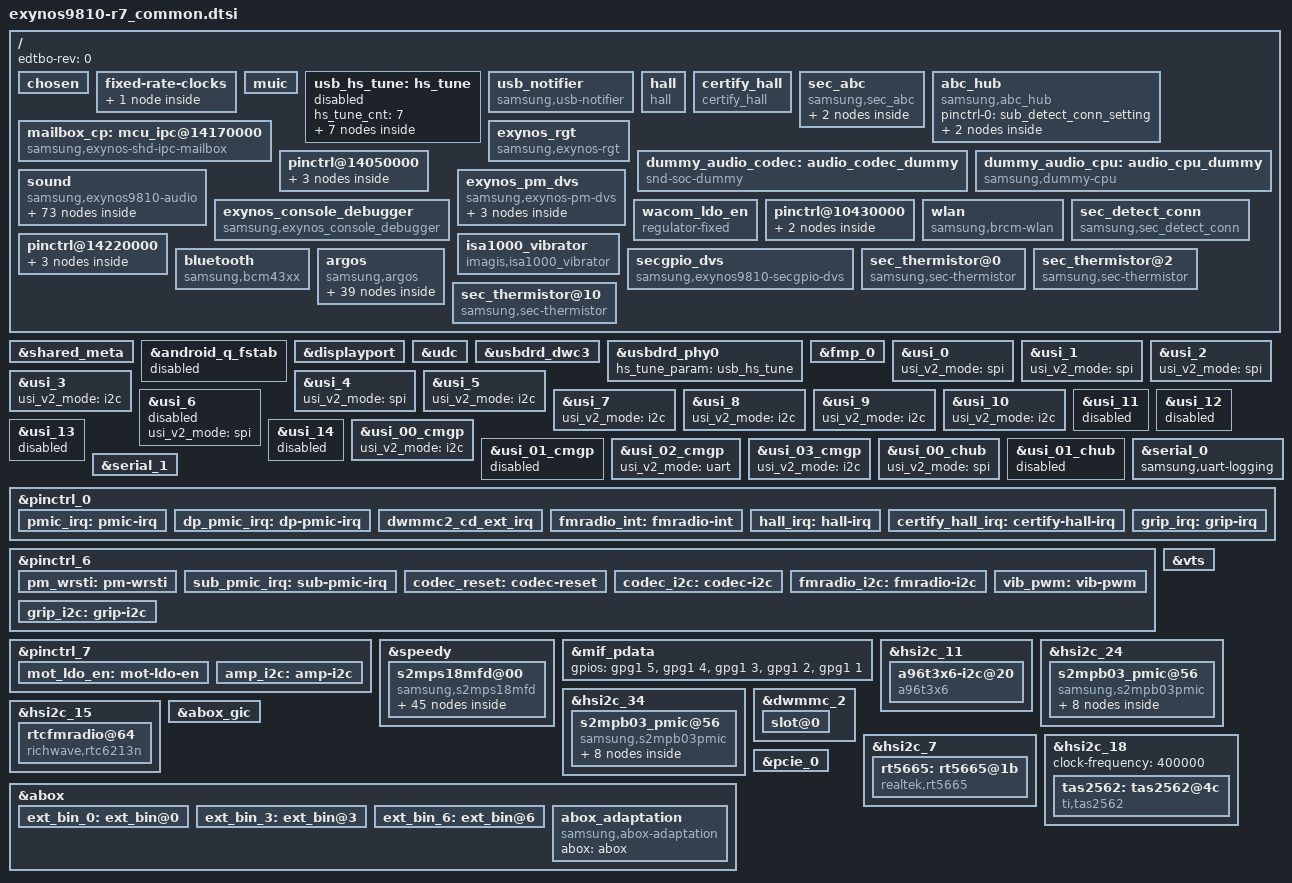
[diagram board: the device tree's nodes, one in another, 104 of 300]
/*
 * SAMSUNG EXYNOS9810 board device tree source
 *
 * Copyright (c) 2017 Samsung Electronics Co., Ltd.
 *		http://www.samsung.com
 *
 * This program is free software; you can redistribute it and/or modify
 * it under the terms of the GNU General Public License version 2 as
 * published by the Free Software Foundation.
*/

#include <dt-bindings/clock/exynos9810.h>
#include <dt-bindings/interrupt-controller/exynos9810.h>
#include <dt-bindings/camera/fimc_is.h>
#include <dt-bindings/pci/pci.h>
#include "display-lcd_anote_common.dtsi"
#include "modem-ss360ap-sipc-pdata.dtsi"
#include "exynos9810-r7_camera.dtsi"
#include "exynos9810-r7_mst.dtsi"
#include <dt-bindings/gpio/gpio.h>
#include "exynos9810-r7_input_common.dtsi"
#include "exynos9810-rmem_r7.dtsi"

/ {
	edtbo-rev = <0>;

	chosen: chosen {
		bootargs = "console=ram skip_initramfs rootwait ro root=/dev/ram0 init=/init clk_ignore_unused bcm_setup=0xffffff80f8e00000 androidboot.hardware=samsungexynos9810 androidboot.selinux=permissive androidboot.debug_level=0x4948 firmware_class.path=/vendor/firmware ecd_setup=disable reserve-fimc=0xffffff80f9fe0000 pmic_info=0x3 epx_activate=true";
	};

	fragment@model {
		target-path = "/";
		__overlay__ {
			#address-cells = <2>;
			#size-cells = <1>;

			fixed-rate-clocks {
				oscclk {
					compatible = "samsung,exynos9810-oscclk";
					clock-frequency = <26000000>;
				};
			};

			muic {
				new_factory;
				dcd_timeout;
			};

			usb_hs_tune:hs_tune {
				status = "disabled";
				hs_tune_cnt = <7>;
				/* value = <device host> */
				hs_tune1 {
					tune_name = "tx_pre_emp";
					tune_value = <0x3 0x3>;
				};

				hs_tune2 {
					tune_name = "tx_vref";
					tune_value = <0xf 0xd>;
				};

				hs_tune3 {
					tune_name = "rx_sqrx";
					tune_value = <0x7 0x7>;
				};

				hs_tune4 {
					tune_name = "compdis";
					tune_value = <0x7 0x7>;
				};

				hs_tune5 {
					tune_name = "tx_res";
					tune_value = <0x3 0x3>;
				};

				hs_tune6 {
					tune_name = "tx_rise";
					tune_value = <0x1 0x1>;
				};

				hs_tune7 {
					tune_name = "utmi_clk";
					tune_value = <0x1 0x1>;
				};
			};

			usb_notifier {
				compatible = "samsung,usb-notifier";
				udc = <&udc>;
				/*
				 * USB_LDOCONTROL_EXYNOS8895	1
				 * USB_LDOCONTROL_EXYNOS9810	2
				*/
				usb-ldocontrol = <2>;
			};

			hall {
				status = "okay";
				compatible = "hall";
				pinctrl-names = "default";
				pinctrl-0 = <&hall_irq>;
				hall,gpio_flip_cover = <&gpa0 2 0>;
			};

			certify_hall {
				status = "okay";
				compatible = "certify_hall";
				pinctrl-names = "default";
				pinctrl-0 = <&certify_hall_irq>;
				certify_hall,gpio_certify_cover = <&gpa3 6 0>;
			};

			sec_abc {
				compatible = "samsung,sec_abc";
				status = "okay";

				gpu {
					gpu,label="GPU fault";
					gpu,threshold_count=<20>;
					gpu,threshold_time=<1200>;
				};
				aicl {
					aicl,label="battery aicl";
					aicl,threshold_count=<5>;
					aicl,threshold_time=<300>;
				};
			};

			abc_hub {
				compatible = "samsung,abc_hub";
				status = "okay";

				pinctrl-names = "default";
				pinctrl-0 = <&sub_detect_conn_setting>;
				
				cond {
					cond,det_conn_gpios = <&gpm6 0 0>;             /* SUB_DET */

					cond,name="sub_cond";
					cond,det_conn_irq_type =<3>; /* SUB_DET BOTH EDGE*/
				};

				bootc {
					bootc,time_spec_user = <100000>; /* user binary user build */
					bootc,time_spec_eng = <100000>; /* user binary eng build */
					bootc,time_spec_fac = <100000>; /* factory binary */
				};
			};

			mailbox_cp: mcu_ipc@14170000 {
				compatible = "samsung,exynos-shd-ipc-mailbox";
				reg = <0x0 0x14170000 0x180>;
				mcu,name = "mcu_ipc_cp";
				mcu,id = <0>;
				interrupts = <0 INTREQ__MAILBOX_CP2AP 0 >;
			};

			exynos_rgt {
			        compatible = "samsung,exynos-rgt";
			};

			dummy_audio_codec: audio_codec_dummy {
				status = "okay";
				compatible = "snd-soc-dummy";
			};

			dummy_audio_cpu: audio_cpu_dummy {
				compatible = "samsung,dummy-cpu";
				status = "okay";
			};

			pinctrl@14050000 {
				codec_irq: codec-irq {
					samsung,pins = "gpa2-2";
					samsung,pin-function = <0xf>;
					samsung,pin-pud = <0>;
				};
			};
			sound {
				status = "okay";
				compatible = "samsung,exynos9810-audio";

				clock-names = "xclkout";
				clocks = <&clock OSC_AUD>;

				samsung,routing =
					"HEADSETMIC", "MICBIAS1",
					"MAINMIC", "MICBIAS2",
					"SUBMIC", "MICBIAS3",
					"IN1P", "HEADSETMIC",
					"IN1N", "HEADSETMIC",
					"IN2P", "MAINMIC",
					"IN2N", "MAINMIC",
					"IN3P", "FM",
					"IN3N", "FM",
					"IN4P", "SUBMIC",
					"IN4N", "SUBMIC",
					"RECEIVER", "MONOOUT",
					"RECEIVER", "MONOOUT",
					"HEADPHONE", "HPOL",
					"HEADPHONE", "HPOR",
					"BLUETOOTH SPK", "ABOX UAIF3 Playback",
					"ABOX UAIF3 Capture", "BLUETOOTH MIC",
					"VOUTPUT", "ABOX UAIF0 Playback",
					"ABOX UAIF1 Capture", "VINPUT1",
					"SPEAKER", "OUT",
					"VOUTPUTCALL", "ABOX UAIF2 Playback",
					"ABOX UAIF2 Capture", "VINPUTCALL";

				samsung,codec = <&abox &abox_uaif_0 &abox_uaif_1 &abox_uaif_2
					&abox_uaif_3 &abox_dsif &vts>;
				samsung,aux = <&abox_effect>;

				rdma@0 {
					cpu {
						sound-dai = <&abox 0>;
					};
					codec {
						sound-dai = <&dummy_audio_codec>;
					};
				};
				rdma@1 {
					cpu {
						sound-dai = <&abox 1>;
					};
					codec {
						sound-dai = <&dummy_audio_codec>;
					};
				};
				rdma@2 {
					cpu {
						sound-dai = <&abox 2>;
					};
					codec {
						sound-dai = <&dummy_audio_codec>;
					};
				};
				rdma@3 {
					cpu {
						sound-dai = <&abox 3>;
					};
					codec {
						sound-dai = <&dummy_audio_codec>;
					};
				};
				rdma@4 {
					cpu {
						sound-dai = <&abox 4>;
					};
					codec {
						sound-dai = <&dummy_audio_codec>;
					};
				};
				rdma@5 {
					cpu {
						sound-dai = <&abox 5>;
					};
					codec {
						sound-dai = <&dummy_audio_codec>;
					};
				};
				rdma@6 {
					cpu {
						sound-dai = <&abox 6>;
					};
					codec {
						sound-dai = <&dummy_audio_codec>;
					};
				};
				rdma@7 {
					cpu {
						sound-dai = <&abox 7>;
					};
					codec {
						sound-dai = <&dummy_audio_codec>;
					};
				};
				wdma@0 {
					cpu {
						sound-dai = <&abox 8>;
					};
					codec {
						sound-dai = <&dummy_audio_codec>;
					};
				};
				wdma@1 {
					cpu {
						sound-dai = <&abox 9>;
					};
					codec {
						sound-dai = <&dummy_audio_codec>;
					};
				};
				wdma@2 {
					cpu {
						sound-dai = <&abox 10>;
					};
					codec {
						sound-dai = <&dummy_audio_codec>;
					};
				};
				wdma@3 {
					cpu {
						sound-dai = <&abox 11>;
					};
					codec {
						sound-dai = <&dummy_audio_codec>;
					};
				};
				wdma@4 {
					cpu {
						sound-dai = <&abox 12>;
					};
					codec {
						sound-dai = <&dummy_audio_codec>;
					};
				};
				vts@0 {
					cpu {
						sound-dai = <&vts 0>;
					};
					codec {
						sound-dai = <&dummy_audio_codec>;
					};
				};
				vts@1 {
					cpu {
						sound-dai = <&vts 1>;
					};
					codec {
						sound-dai = <&dummy_audio_codec>;
					};
				};
				dp_audio@0 {
					cpu {
						sound-dai = <&dummy_audio_cpu>;
					};
					codec {
						sound-dai = <&dummy_audio_codec>;
					};
				};
				uaif@0 {
					cpu {
						sound-dai = <&abox_uaif_0>;
					};
					codec {
						sound-dai = <&rt5665 0>;
					};
				};
				uaif@1 {
					cpu {
						sound-dai = <&abox_uaif_1>;
					};
					platform {
						sound-dai = <&abox_adaptation 0>;
					};
					codec {
						sound-dai = <&tas2562 0>;
					};
				};
				uaif@2 {
					cpu {
						sound-dai = <&abox_uaif_2>;
					};
					codec {
						sound-dai = <&rt5665 4>;
					};
				};
				uaif@3 {
					cpu {
						sound-dai = <&abox_uaif_3>;
					};
					codec {
						sound-dai = <&dummy_audio_codec>;
					};
				};
				dsif@0 {
					cpu {
						sound-dai = <&abox_dsif>;
					};
					codec {
						sound-dai = <&dummy_audio_codec>;
					};
				};
				sifs0@0 {
					cpu {
						sound-dai = <&abox 13>;
					};
					codec {
						sound-dai = <&dummy_audio_codec>;
					};
				};
				sifs1@0 {
					cpu {
						sound-dai = <&abox 14>;
					};
					codec {
						sound-dai = <&dummy_audio_codec>;
					};
				};
				sifs2@0 {
					cpu {
						sound-dai = <&abox 15>;
					};
					codec {
						sound-dai = <&dummy_audio_codec>;
					};
				};
				/*
				debug-trace@1 {
					cpu {
						sound-dai = <&cs47l93 6>;
					};
					codec {
						sound-dai = <&cs47l93 7>;
					};
				};
				*/
			};

		       exynos_console_debugger {
			       compatible = "samsung,exynos_console_debugger";
			       reg = <0x0 0x10440000 0x100>;
			       interrupts = <0 INTREQ__UART_DBG 0>;
			       interrupt-names = "uart_irq";
			       pinctrl-names = "default";
			       pinctrl-0 = <&uart0_bus>;
			       uart_port = <0>;
			       /* <sfr_base_address sfr_size> */
			       sfr_reg = <0x10000000 0x10000000>;
			       samsung,usi-serial-v2;
			       status = "ok";
		       };

		       exynos_pm_dvs {
			       compatible = "samsung,exynos-pm-dvs";
			       vdd_lldo1 {
				       regulator_name = "vdd_lldo1";
				       suspend_volt = <800000>;
				       init_volt = <850000>;
				       volt_range_step = <62500>;
			       };

			       vdd_lldo3 {
				       regulator_name = "vdd_lldo3";
				       suspend_volt = <1250000>;
				       init_volt = <1300000>;
				       volt_range_step = <62500>;
			       };
			       vdd_mldo {
				       regulator_name = "vdd_mldo";
				       suspend_volt = <1850000>;
				       init_volt = <2000000>;
				       volt_range_step = <12500>;
			       };
		       };

			wacom_ldo_en: wacom_ldo_en {
				compatible = "regulator-fixed";
				regulator-name = "wacom_3.3v";
				regulator-min-microvolt = <3300000>;
				regulator-max-microvolt = <3300000>;
				gpio = <&gpm42 0 0>;
				enable-active-high;
				regulator-boot-on;
			};

			pinctrl@10430000 {
				cfg_wlanen: cfg_wlanen {
					samsung,pins = "gpg0-5";
					samsung,pin-function = <1>;
					samsung,pin-pud = <0>;
					samsung,pin-drv = <3>;
					samsung,pin-con-pdn = <3>;
				};
			};

			wlan {
				compatible = "samsung,brcm-wlan";
				gpios = <&gpg0 5 0x1 /* WLAN_EN */
			 			&gpa0 7 0x1 /* WLAN HOST WAKE GPIO_0 */>;
				pinctrl-names = "default";
				pinctrl-0 = <&cfg_wlanen &wlan_host_wake>;
				status = "okay";
			};
			
			sec_detect_conn {
				compatible = "samsung,sec_detect_conn";
				sec,det_conn_gpios = <&gpm6 0 0>;             /* SUB_DET */
				sec,det_conn_name = "SUB_CONNECT";

				sec,det_conn_irq_type = <3>; /* SUB_DET BOTH EDGE*/

				pinctrl-names = "default";
				pinctrl-0 = <&sub_detect_conn_setting>;
			};
			
			pinctrl@14220000 {
				sub_detect_conn_setting: sub_detect_conn_setting {
					samsung,pins = "gpm6-0";
					samsung,pin-function = <0xf>;
					samsung,pin-pud = <0>;
					samsung,pin-drv = <0>;
				};
			};

			isa1000_vibrator {
				compatible = "imagis,isa1000_vibrator";
				status = "okay";
				pinctrl-names = "default";
				pinctrl-0 = <&vib_pwm &mot_ldo_en>;
				pwms = <&sec_pwm 1 50000 0>;
				isa1000,duty_ratio = <96>;
				isa1000,temp_duty_ratio = <68>;
				isa1000,temperature = <550>; /* 55.0 Celsius */
				/* for multi-frequency */
				isa1000,multi_frequency = <7>;
				/* frequency       alert low  mid  high  0  press release */
				isa1000,frequency = <1595 1200 1500 2000 1800 2000 2000>;
				isa1000,gpio_en = <&gpg3 6 1>;
				isa1000,motor_type = "LINEAR_1040";
			};

			pinctrl@14220000 {
				bt_en: bt-en {
					samsung,pins ="gpm43-0";
					samsung,pin-function = <1>;
					samsung,pin-pud = <0>;
					samsung,pin-con-pdn = <3>;
					samsung,pin-pud-pdn = <0>;
				};
			};

			pinctrl@10430000 {
				bt_btwake: bt-btwake {
					samsung,pins = "gpg2-0";
					samsung,pin-function = <1>;
					samsung,pin-pud = <0>;
					samsung,pin-con-pdn = <3>;
					samsung,pin-pud-pdn = <0>;
				};
			};

			pinctrl@14050000 {
				bt_hostwake: bt-hostwake {
					samsung,pins = "gpa2-3";
					samsung,pin-function = <0>;
					samsung,pin-pud = <0>;
				};
				amp_en: amp-en {
					samsung,pins = "gpa2-7";
					samsung,pin-function = <1>;
					samsung,pin-pud = <0>;
				};
			};

			bluetooth {
				compatible = "samsung,bcm43xx";
				gpios = <&gpm43 0 0    /*BT_EN*/
					&gpg2 0 0    /*BT_WAKE*/
					&gpa2 3 0xF    /*BT_HOST_WAKE*/ >;
				pinctrl-names = "default";
				pinctrl-0=<&bt_hostwake &bt_btwake>;
				status = "okay";
			};
			pinctrl@14220000 {
				amp_int: amp-int {
					samsung,pins ="gpm2-0";
					samsung,pin-function = <0xf>;
					samsung,pin-pud = <0>;
					samsung,pin-pud-pdn = <0>;
				};
			};

			secgpio_dvs {
				compatible = "samsung,exynos9810-secgpio-dvs";
				status = "okay";
			};

			argos {
				compatible = "samsung,argos";
				#address-cells = <1>;
				/*  The device number should be assigned for each device, e.g. "boot_device@1" and "boot_device@2".
				 * Duplicated number is not allowed. Please refer the below example.
				 */

				/* Table Format
				 * threshold : throughput threshold(Mbps)
				 * big_min : Big Core's minimum frequency lock. 0 means not set,
				 * big_max : Big Core's maximum frequency lock. 0 means not set,
				 * lit_min : Little Core's minimum frequency lock. 0 means not set,
				 * lit_max : Little Core's maximum frequency lock. 0 means not set,
				 * mif : MIF frequency lock. 0 means not set,
				 * int : INT frequency lock. 0 means not set,
				 * task_affinity : "enable" - Set task affinity lock.
				 *	           "disable" - Not set or unlock,
				 *		   Task affinity should be predefined driver's code.
				 * irq_affinity : "enable" - Set irq affinity lock.
				 *                "disable" - Not set or unlock,
				 *		  IRQ affinity should be predefined driver's code.
				 * hmp_boot : "enable" - Increase hmp boosting count
				 *            "disable" - Decrease hmp boosting count
				 */

				boot_device@1 {
					net_boost,label="UFS";
					net_boost,node="";
					net_boost,sysnode="/sys/class/scsi_host/host0/transferred_cnt";
					net_boost,table {
						level_0 {
							threshold = <400>; /* Mbps */
							lit_min = <1456000>;
							mif = <1352000>;
						};
						level_1 {
							threshold = <800>; /* Mbps */
							big_min = <1066000>;
							lit_min = <1456000>;
							mif = <1539000>;
							hmp_boost = "enable";
						};
					};
				};
				boot_device@2 {
					net_boost,label="WIFI TX";
					net_boost,node="wlan0";
					net_boost,slowdown;
					net_boost,table {
						level_0 {
							threshold = <60>;
							big_min = <1469000>;
							lit_min = <1456000>;
						};
						level_1 {
							threshold = <150>;
							big_min = <1690000>;
							lit_min = <1690000>;
						};
						level_2 {
							threshold = <200>;
							big_min = <1924000>;
							lit_min = <1794000>;
							mif = <1352000>;
							int = <400000>;
							task_affinity = "enable";
							irq_affinity = "enable";
							hmp_boost = "enable";
						};
						level_3 {
							threshold = <300>;
							big_min = <2002000>;
							lit_min = <1794000>;
							mif = <1794000>;
							int = <534000>;
							task_affinity = "enable";
							irq_affinity = "enable";
							hmp_boost = "enable";
						};
					};
				};
				boot_device@3 {
					net_boost,label="WIFI RX";
					net_boost,node="wlan0";
					net_boost,slowdown;
					net_boost,table {
						level_0 {
							threshold = <100>;
							big_min = <1170000>;
							lit_min = <1053000>;
						};
						level_1 {
							threshold = <150>;
							big_min = <1469000>;
							lit_min = <1248000>;
						};
						level_2 {
							threshold = <200>;
							big_min = <1690000>;
							lit_min = <1248000>;
							mif = <845000>;
							int = <400000>;
							task_affinity = "enable";
							irq_affinity = "enable";
							hmp_boost = "enable";
						};
						level_3 {
							threshold = <300>;
							big_min = <1924000>;
							lit_min = <1456000>;
							mif = <1352000>;
							int = <534000>;
							task_affinity = "enable";
							irq_affinity = "enable";
							hmp_boost = "enable";
						};
					};
				};
				boot_device@4 {
					net_boost,label="P2P";
					net_boost,node="p2p-wlan0-0";
					net_boost,slowdown;
					net_boost,table {
						level_0 {
							threshold = <60>;
							big_min = <1469000>;
							lit_min = <1456000>;
						};
						level_1 {
							threshold = <150>;
							big_min = <1690000>;
							lit_min = <1690000>;
						};
						level_2 {
							threshold = <200>;
							big_min = <1924000>;
							lit_min = <1794000>;
							mif = <1352000>;
							int = <400000>;
							task_affinity = "enable";
							irq_affinity = "enable";
							hmp_boost = "enable";
						};
						level_3 {
							threshold = <300>;
							big_min = <2002000>;
							lit_min = <1794000>;
							mif = <1794000>;
							int = <534000>;
							task_affinity = "enable";
							irq_affinity = "enable";
							hmp_boost = "enable";
						};
					};
				};
				boot_device@5 {
					net_boost,label="NAN";
					net_boost,node="aware_data0";
					net_boost,slowdown;
					net_boost,table {
						level_0 {
							threshold = <60>;
							big_min = <1469000>;
							lit_min = <1456000>;
						};
						level_1 {
							threshold = <150>;
							big_min = <1690000>;
							lit_min = <1690000>;
						};
						level_2 {
							threshold = <200>;
							big_min = <1924000>;
							lit_min = <1794000>;
							mif = <1352000>;
							int = <400000>;
							task_affinity = "enable";
							irq_affinity = "enable";
							hmp_boost = "enable";
						};
						level_3 {
							threshold = <300>;
							big_min = <2002000>;
							lit_min = <1794000>;
							mif = <1794000>;
							int = <534000>;
							task_affinity = "enable";
							irq_affinity = "enable";
							hmp_boost = "enable";
						};
					};
				};
				boot_device@6 {
					net_boost,label="IPC";
					net_boost,node="rmnet0 rmnet1 rmnet2 rmnet3 rmnet4 rmnet5 rmnet6 rmnet7 umts_dm0";
					net_boost,table {
						level_0 {
							threshold = <100>;
							lit_min = <1053000>;
							mif = <845000>;
						};
						level_1 {
							threshold = <150>;
							lit_min = <1248000>;
							mif = <1014000>;
						};
						level_2 {
							threshold = <200>;
							big_min = <1924000>;
							lit_min = <1690000>;
							mif = <1794000>;
						};
					};
				};
				boot_device@7 {
					net_boost,label="CLAT";
					net_boost,node="clat clat4 v4-rmnet0 v4-rmnet1 v4-rmnet2 v4-rmnet3 v4-rmnet4 v4-rmnet5 v4-rmnet6 v4-rmnet7";
					net_boost,table {
						level_0 {
							threshold = <100>;
							big_min = <1066000>;
							mif = <1014000>;
						};
						level_1 {
							threshold = <200>;
							big_min = <1117000>;
							mif = <1794000>;
						};
						level_2 {
							threshold = <300>;
							big_min = <1261000>;
							mif = <1794000>;
						};
						level_3 {
							threshold = <400>;
							big_min = <1469000>;
							mif = <1794000>;
						};
					};
				};
			};

			sec_thermistor@0 {
				compatible = "samsung,sec-thermistor";
				status = "okay";
				thermistor_name = "sec-ap-thermistor";
				id = <0>;

				adc_array = <275 336 408 482 561 661 778 894 1045 1209
					1385 1605 1791 2031 2298 2486 2714 2931 3136 3302
					3456 3574 3678>;
				temp_array = <900 850 800 750 700 650 600 550 500 450
					400 350 300 250 200 150 100 50 0 (-50)
					(-100) (-150) (-200)>;

				io-channels = <&exynos_adc 0>;
				io-channel-names = "adc-ap-temp";
				io-channel-ranges;
			};

			sec_thermistor@2 {
				compatible = "samsung,sec-thermistor";
				status = "okay";
				thermistor_name = "sec-wf-thermistor";
				id = <1>;

				adc_array = <275 336 408 482 561 661 778 894 1045 1209
					1385 1605 1791 2031 2298 2486 2714 2931 3136 3302
					3456 3574 3678>;
				temp_array = <900 850 800 750 700 650 600 550 500 450
					400 350 300 250 200 150 100 50 0 (-50)
					(-100) (-150) (-200)>;

				io-channels = <&exynos_adc 2>;
				io-channel-names = "adc-wf-temp";
				io-channel-ranges;
			};

			sec_thermistor@10 {
				compatible = "samsung,sec-thermistor";
				status = "okay";
				thermistor_name = "sec-pa-thermistor";
				id = <2>;

				adc_array = <327 347 367 388 410 433 456 482 507 534
					562 591 621 651 684 717 750 786 821 858
					896 935 975 1016 1057 1100 1143 1187 1231 1277
					1323 1369 1416 1463 1511 1559 1608 1657 1706 1755
					1804 1853 1902 1951 2000 2048 2096 2144 2192 2239
					2285 2332 2378 2421 2467 2510 2553 2596 2637 2678
					2719 2758 2797 2833 2872 2906 2942 2976 3011 3042
					3074 3106 3136 3165 3195 3222 3249 3277 3302 3327
					3352 3375 3397 3420 3441 3461 3482 3502 3520 3538
					3557 3573 3591 3607 3620 3636 3650 3666 3680 3691
					3705 3716 3730 3741 3752 3761 3773 3782 3793 3802
					3812>;

				temp_array =
					<(-200) (-190) (-180) (-170) (-160) (-150) (-140) (-130) (-120) (-110)
					(-100) (-90) (-80) (-70) (-60) (-50) (-40) (-30) (-20) (-10)
					0 10 20 30 40 50 60 70 80 90
					100 110 120 130 140 150 160 170 180 190
					200 210 220 230 240 250 260 270 280 290
					300 310 320 330 340 350 360 370 380 390
					400 410 420 430 440 450 460 470 480 490
					500 510 520 530 540 550 560 570 580 590
					600 610 620 630 640 650 660 670 680 690
					700 710 720 730 740 750 760 770 780 790
					800 810 820 830 840 850 860 870 880 890
					900>;

				io-channels = <&exynos_adc 10>;
				io-channel-names = "adc-pa-temp";
				io-channel-ranges;
			};

		}; /* end of __overlay__ */
	}; /* end of fragment */
}; /* end of root */

/***** reference symbol node *****/

&shared_meta {
	status = "okay";
	parts = "vbmeta,boot,system,vendor,product,odm,prism,optics,vbmeta_samsung,recovery,dtbo,keystorage";
};

&android_q_fstab {
	status = "disabled";
};

&displayport {
};

&udc {
	status = "okay";
};

&usbdrd_dwc3 {
	dr_mode = "otg";
	maximum-speed = "high-speed";
	phys = <&usbdrd_phy0 0>;
	phy-names = "usb2-phy";
	snps,quirk-frame-length-adjustment = <0x20>;
	snps,u1u2_exitfail_quirk;
	/*
	 * dis-u2-freeclk-exists-quirk, dis_u2_susphy_quirk are alternative.
	 * One of them should be selected
	 */
	snps,dis-u2-freeclk-exists-quirk;
	/* snps,dis_u2_susphy_quirk;*/
};

&usbdrd_phy0 {
	status = "okay";
	hs_tune_param = <&usb_hs_tune>;
};

&fmp_0 {
	exynos,block-type = "sda";
	exynos,fips-block_offset = <5>;
};

&usi_0 {
	usi_v2_mode = "spi";
	status = "okay";
};

&usi_1 {
	usi_v2_mode = "spi";
	status = "okay";
};

&usi_2 {
	usi_v2_mode = "spi";
	status = "okay";
};

&usi_3 {
	usi_v2_mode = "i2c";
	status = "okay";
};

&usi_4 {
	usi_v2_mode = "spi";
	status = "okay";
};

&usi_5 {
	usi_v2_mode = "i2c";
	status = "okay";
};

&usi_6 {
	usi_v2_mode = "spi";
	status = "disabled";
};

&usi_7 {
	usi_v2_mode = "i2c";
	status = "okay";
};

&usi_8 {
	usi_v2_mode = "i2c";
	status = "okay";
};

&usi_9 {
	usi_v2_mode = "i2c";
	status = "okay";
};

&usi_10 {
	usi_v2_mode = "i2c";
	status = "okay";
};

&usi_11 {
	status = "disabled";
};

&usi_12 {
	status = "disabled";
};

&usi_13 {
	status = "disabled";
};

&usi_14 {
	status = "disabled";
};

&usi_00_cmgp {
	usi_v2_mode = "i2c";
	status = "okay";
};

/* USI_01_CMGP */
&usi_01_cmgp {
	status = "disabled";
};

/* USI_02_CMGP */
&usi_02_cmgp {
	usi_v2_mode = "uart";
	status = "okay";
};

/* USI_03_CMGP */
&usi_03_cmgp {
	usi_v2_mode = "i2c";
	status = "okay";
};

/* USI_00_CHUB */
&usi_00_chub {
	usi_v2_mode = "spi";
	status = "okay";
};

/* USI_01_CHUB */
&usi_01_chub {
	status = "disabled";
};

&chosen {
	bootargs_ext = "rootwait ro root=/dev/ram0 init=/init androidboot.boot_devices=11120000.ufs";
};

&serial_0 {
	samsung,uart-logging;
	status = "okay";
};

&serial_1 {
	samsung,uart-logging;
	samsung,uart-panic-log;
	status = "okay";
};

&pinctrl_0 {
	pmic_irq: pmic-irq {
		samsung,pins = "gpa0-1";
		samsung,pin-pud = <3>;
		samsung,pin-drv = <3>;
	};

	dp_pmic_irq: dp-pmic-irq {
		samsung,pins = "gpa1-4";
		samsung,pin-function = <0>;
		samsung,pin-pud = <0>;
		samsung,pin-drv = <0>;
	};

	dwmmc2_cd_ext_irq: dwmmc2_cd_ext_irq {
		samsung,pins = "gpa1-5";
		samsung,pin-function = <0xf>;
		samsung,pin-pud = <0>;
		samsung,pin-drv = <4>;
	};

	fmradio_int: fmradio-int {
		samsung,pins = "gpa2-1";
		samsung,pin-function = <0xf>;
		samsung,pin-pud = <0>;
		samsung,pin-drv = <3>;
		samsung,pin-con-pdn =<3>;
		samsung,pin-pud-pdn = <0>;
	};

	hall_irq: hall-irq {
		samsung,pins = "gpa3-6";
		samsung,pin-function = <0xf>;
		samsung,pin-pud = <1>;
		samsung,pin-drv = <0>;
	};

	certify_hall_irq: certify-hall-irq {
		samsung,pins = "gpa0-2";
		samsung,pin-function = <0xf>;
		samsung,pin-pud = <0>;
		samsung,pin-drv = <0>;
	};

	grip_irq: grip-irq {
		samsung,pins = "gpa3-0";
		samsung,pin-function = <0xf>;
		samsung,pin-pud = <0>;
		samsung,pin-drv = <3>;
	};
};

&pinctrl_6 {
	/* Warm reset information from AP */
	pm_wrsti: pm-wrsti {
		samsung,pins = "gpg0-1";
		samsung,pin-con-pdn = <3>;
		samsung,pin-pud-pdn = <0>;
	};
	sub_pmic_irq: sub-pmic-irq {
		samsung,pins = "gpg2-1";
		samsung,pin-function = <0>;
		samsung,pin-pud = <0>;
		samsung,pin-drv = <0>;
	};

	codec_reset: codec-reset {
		samsung,pins ="gpg1-0";
		samsung,pin-con-pdn =<3>;
		samsung,pin-pud-pdn = <1>;
	};

	codec_i2c: codec-i2c {
		samsung,pins = "gpp0-6", "gpp0-7";
		samsung,pin-pud-pdn = <0>;
	};

	fmradio_i2c: fmradio-i2c {
		samsung,pins = "gpp2-6", "gpp2-7";
		samsung,pin-pud-pdn = <0>;
	};

	vib_pwm: vib-pwm {
		samsung,pins = "gpp3-1";
		samsung,pin-function = <2>;
		samsung,pin-pud = <1>;
		samsung,pin-drv = <0>;
		samsung,pin-con-pdn = <3>;
		samsung,pin-pud-pdn = <1>;
	};

	grip_i2c: grip-i2c {
		samsung,pins = "gpp1-6", "gpp1-7";
		samsung,pin-function = <3>;
		samsung,pin-pud = <0>;
		samsung,pin-con-pdn = <2>; /* input */
		samsung,pin-pud-pdn = <0>;
	};
};

&pinctrl_7 {
	mot_ldo_en: mot-ldo-en {
		samsung,pins = "gpg3-6";
		samsung,pin-function = <1>;
		samsung,pin-pud = <0>;
		samsung,pin-drv = <0>;
		samsung,pin-con-pdn = <3>;
		samsung,pin-pud-pdn = <0>;
	};
	amp_i2c: amp-i2c {
		samsung,pins = "gpp4-4", "gpp4-5";
		samsung,pin-pud-pdn = <0>;
	};
};

&vts {
	pinctrl-0 = <>;
	pinctrl-1 = <>;
	pinctrl-2 = <>;

};

&speedy {
	#address-cells = <1>;
	#size-cells = <0>;
	status = "okay";
	s2mps18mfd@00 {
		compatible = "samsung,s2mps18mfd";
		acpm-ipc-channel = <2>;
		i2c-speedy-address;
		s2mps18,wakeup = "enabled";
		s2mps18,irq-gpio = <&gpa0 1 0>;
		reg = <0x00>;
		interrupts = <1 0 0>;
		interrupt-parent = <&gpa0>;
		pinctrl-names = "default";
		pinctrl-0 = <&pmic_irq &pm_wrsti &smpl_warn>;
		gpios = <&gpg0 3 0>;
		smpl_warn_en = <1>; /* 1 : enable , 0 : disable */
		/* range of smpl_warn_vth */
		/* 0x00 : 2.1V, 0x20 : 2.3V, 0x40 : 2.5V, 0x60 : 2.7V 0x80 : 2.9V */
		/* 0xA0 : 3.1V, 0xC0 : 3.3V, 0xE0 : 3.5V */
		smpl_warn_vth = <0x80>;
		/* LowBat_Hys[4:3] 00(100mV), 01(200mV), 10(300mV), 11(400mV) */
		smpl_warn_hys = <0x00>;
		adc_mode = <1>; /* 0 : disable, 1 : current meter, 2 : power meter */
		adc_sync_mode = <2>; /* 1 : sync mode, 2 : async mode */
		g3d_en = <1>; /* 1 : enable , 0 : disable */
		cpu_ocp_warn_en = <1>; /* 1 : enable, 0 : disable */
		cpu_ocp_warn_reset = <0>; /* 0 : 2 clock, 1 : 32 clock */
		cpu_ocp_warn_lv = <0x0>; /* step : -250mA */
		gpu_ocp_warn_en = <1>; /* 1: enable, 0 : disable */
		gpu_ocp_warn_reset = <1>; /* 0 : 2 clock, 1 : 32 clock */
		gpu_ocp_warn_lv = <0x0>; /* step : -166mA */
		/* RTC: wtsr/smpl */
		wtsr_en = "enabled"; /* enable */
		smpl_en = "enabled"; /* enable */
		wtsr_timer_val = <3>;	/* 1000ms */
		smpl_timer_val = <0>;	/* 100ms */
		check_jigon = <0>; /* do not check jigon */
		/* RTC: If it's first boot, reset rtc to 1/1/2017 12:00:00(Sun) */
		init_time,sec = <0>;
		init_time,min = <0>;
		init_time,hour = <12>;
		init_time,mday = <1>;
		init_time,mon = <0>;
		init_time,year = <117>;
		init_time,wday = <0>;

		regulators {
			buck1_reg: BUCK1 {
				regulator-name = "vdd_mif";
				regulator-min-microvolt = <450000>;
				regulator-max-microvolt = <950000>;
				regulator-always-on;
				regulator-ramp-delay = <6000>;
				regulator-initial-mode = <2>;
			};
			buck2_reg: BUCK2 {
				regulator-name = "vdd_cpucl1";
				regulator-min-microvolt = <450000>;
				regulator-max-microvolt = <1300000>;
				regulator-always-on;
				regulator-ramp-delay = <6000>;
				regulator-initial-mode = <1>;
			};

			buck3_reg: BUCK3 {
				regulator-name = "vdd_cpucl0";
				regulator-min-microvolt = <450000>;
				regulator-max-microvolt = <1300000>;
				regulator-always-on;
				regulator-ramp-delay = <6000>;
				regulator-initial-mode = <1>;
			};

			buck4_reg: BUCK4{
				regulator-name = "vdd_int";
				regulator-min-microvolt = <450000>;
				regulator-max-microvolt = <950000>;
				regulator-always-on;
				regulator-ramp-delay = <6000>;
				regulator-initial-mode = <2>;
			};

			buck5_reg: BUCK5 {
				regulator-name = "vdd_cam";
				regulator-min-microvolt = <450000>;
				regulator-max-microvolt = <950000>;
				regulator-always-on;
				regulator-ramp-delay = <6000>;
				regulator-initial-mode = <2>;
			};

			buck6_reg: BUCK6 {
				regulator-name = "vdd_g3d";
				regulator-min-microvolt = <450000>;
				regulator-max-microvolt = <950000>;
				regulator-always-on;
				regulator-ramp-delay = <6000>;
				regulator-initial-mode = <2>;
			};

			buck7_reg: BUCK7 {
				regulator-name = "vdd_cpucl1_m";
				regulator-min-microvolt = <450000>;
				regulator-max-microvolt = <1300000>;
				regulator-always-on;
				regulator-ramp-delay = <6000>;
				regulator-initial-mode = <1>;
			};

			buck8_reg: BUCK8 {
				regulator-name = "vdd2_mem";
				regulator-min-microvolt = <900000>;
				regulator-max-microvolt = <1300000>;
				regulator-always-on;
				regulator-ramp-delay = <6000>;
				regulator-initial-mode = <3>;
			};

			buck9_reg: BUCK9 {
				regulator-name = "vddq_mem";
				regulator-min-microvolt = <450000>;
				regulator-max-microvolt = <950000>;
				regulator-always-on;
				regulator-ramp-delay = <6000>;
				regulator-initial-mode = <2>;
			};

			buck10_reg: BUCK10 {
				regulator-name = "vdd_lldo1";
				regulator-min-microvolt = <750000>;
				regulator-max-microvolt = <1150000>;
				regulator-always-on;
				regulator-ramp-delay = <6000>;
				regulator-initial-mode = <3>;
			};

			buck11_reg: BUCK11 {
				regulator-name = "vdd_lldo2";
				regulator-min-microvolt = <900000>;
				regulator-max-microvolt = <1300000>;
				regulator-always-on;
				regulator-ramp-delay = <6000>;
				regulator-initial-mode = <3>;
			};

			buck12_reg: BUCK12 {
				regulator-name = "vdd_lldo3";
				regulator-min-microvolt = <1100000>;
				regulator-max-microvolt = <1500000>;
				regulator-always-on;
				regulator-ramp-delay = <6000>;
				regulator-initial-mode = <3>;
			};

			buck13_reg: BUCK13 {
				regulator-name = "vdd_mldo";
				regulator-min-microvolt = <1750000>;
				regulator-max-microvolt = <2150000>;
				regulator-always-on;
				regulator-ramp-delay = <6000>;
				regulator-initial-mode = <3>;
			};

			ldo1_reg: LDO1 {
				regulator-name = "vdd_ldo1";
				regulator-min-microvolt = <700000>;
				regulator-max-microvolt = <950000>;
				regulator-always-on;
				regulator-ramp-delay = <12000>;
				regulator-initial-mode = <3>;
			};

			ldo2_reg: LDO2 {
				regulator-name = "vqmmc";
				regulator-min-microvolt = <1700000>;
				regulator-max-microvolt = <2950000>;
				regulator-ramp-delay = <12000>;
			};

			ldo3_reg: LDO3 {
				regulator-name = "vdd_ldo3";
				regulator-min-microvolt = <1600000>;
				regulator-max-microvolt = <1950000>;
				regulator-always-on;
				regulator-ramp-delay = <12000>;
				regulator-initial-mode = <3>;
			};

			ldo4_reg: LDO4 {
				regulator-name = "vdd_ldo4";
				regulator-min-microvolt = <700000>;
				regulator-max-microvolt = <1100000>;
				regulator-always-on;
				regulator-ramp-delay = <12000>;
				regulator-initial-mode = <1>;
			};

			ldo5_reg: LDO5 {
				regulator-name = "vdd_ldo5";
				regulator-min-microvolt = <1600000>;
				regulator-max-microvolt = <1950000>;
				regulator-always-on;
				regulator-ramp-delay = <12000>;
				regulator-initial-mode = <1>;
			};

			ldo6_reg: LDO6 {
				regulator-name = "vdd_ldo6";
				regulator-min-microvolt = <450000>;
				regulator-max-microvolt = <950000>;
				regulator-always-on;
				regulator-ramp-delay = <12000>;
				regulator-initial-mode = <1>;
			};

			ldo7_reg: LDO7 {
				regulator-name = "vdd_ldo7";
				regulator-min-microvolt = <450000>;
				regulator-max-microvolt = <950000>;
				regulator-always-on;
				regulator-ramp-delay = <12000>;
				regulator-initial-mode = <1>;
			};

			ldo8_reg: LDO8 {
				regulator-name = "vdd_ldo8";
				regulator-min-microvolt = <700000>;
				regulator-max-microvolt = <1300000>;
				regulator-always-on;
				regulator-ramp-delay = <12000>;
				regulator-initial-mode = <1>;
			};

			ldo9_reg: LDO9 {
				regulator-name = "vdd_ldo9";
				regulator-min-microvolt = <1600000>;
				regulator-max-microvolt = <1950000>;
				regulator-always-on;
				regulator-ramp-delay = <12000>;
				regulator-initial-mode = <1>;
			};

			ldo10_reg: LDO10 {
				regulator-name = "vdd_ldo10";
				regulator-min-microvolt = <450000>;
				regulator-max-microvolt = <950000>;
				regulator-always-on;
				regulator-ramp-delay = <12000>;
				regulator-initial-mode = <1>;
			};

			ldo11_reg: LDO11 {
				regulator-name = "vdd_ldo11";
				regulator-min-microvolt = <450000>;
				regulator-max-microvolt = <950000>;
				regulator-always-on;
				regulator-ramp-delay = <12000>;
				regulator-initial-mode = <1>;
			};

			ldo12_reg: LDO12 {
				regulator-name = "vdd_ldo12";
				regulator-min-microvolt = <700000>;
				regulator-max-microvolt = <1100000>;
				regulator-always-on;
				regulator-ramp-delay = <12000>;
				regulator-initial-mode = <1>;
			};

			ldo13_reg: LDO13 {
				regulator-name = "vdd_ldo13";
				regulator-min-microvolt = <1600000>;
				regulator-max-microvolt = <1950000>;
				regulator-always-on;
				regulator-ramp-delay = <12000>;
				regulator-initial-mode = <1>;
			};

			ldo14_reg: LDO14 {
				regulator-name = "vdd_ldo14";
				regulator-min-microvolt = <1700000>;
				regulator-max-microvolt = <3350000>;
				regulator-always-on;
				regulator-ramp-delay = <12000>;
				regulator-initial-mode = <1>;
			};

			ldo22_reg: LDO22 {
				regulator-name = "vdd_ldo22";
				regulator-min-microvolt = <700000>;
				regulator-max-microvolt = <1100000>;
				regulator-ramp-delay = <12000>;
				regulator-initial-mode = <0>;
			};

			ldo28_reg: LDO28 {
				regulator-name = "VDDA_2.8V_SUB";
				regulator-min-microvolt = <2800000>;
				regulator-max-microvolt = <2800000>;
				regulator-ramp-delay = <12000>;
				regulator-initial-mode = <0>;
			};

			ldo30_reg: LDO30 {
				regulator-name = "vdd_ldo30";
				regulator-min-microvolt = <450000>;
				regulator-max-microvolt = <1100000>;
				regulator-always-on;
				regulator-ramp-delay = <12000>;
				regulator-initial-mode = <1>;
			};

			ldo31_reg: LDO31 {
				regulator-name = "vmmc";
				regulator-min-microvolt = <2950000>;
				regulator-max-microvolt = <2950000>;
				regulator-ramp-delay = <12000>;
			};

			ldo32_reg: LDO32 {
				regulator-name = "vdd_ldo32";
				regulator-min-microvolt = <1800000>;
				regulator-max-microvolt = <3375000>;
				regulator-always-on;
				regulator-ramp-delay = <12000>;
				regulator-initial-mode = <2>;
			};

			ldo33_reg: LDO33 {
				regulator-name = "regulator_1v8";
				regulator-min-microvolt = <1800000>;
				regulator-max-microvolt = <1800000>;
				regulator-ramp-delay = <12000>;
				regulator-initial-mode = <3>;
				regulator-boot-on;
			};

			ldo34_reg: LDO34 {
				regulator-name = "vdd_ldo34";
				regulator-min-microvolt = <700000>;
				regulator-max-microvolt = <1300000>;
				regulator-always-on;
				regulator-ramp-delay = <12000>;
				regulator-initial-mode = <2>;
			};

			ldo35_reg: LDO35 {
				regulator-name = "VDDIO_1.8V_CAM";
				regulator-min-microvolt = <1800000>;
				regulator-max-microvolt = <1800000>;
			};

			ldo36_reg: LDO36 {
				regulator-name = "regulator_3v3";
				regulator-min-microvolt = <3300000>;
				regulator-max-microvolt = <3300000>;
				regulator-initial-mode = <3>;
				regulator-boot-on;
			};

			ldo37_reg: LDO37 {
				regulator-name = "vdd_ldo37";
				regulator-min-microvolt = <1000000>;
				regulator-max-microvolt = <2275000>;
				regulator-ramp-delay = <12000>;
				regulator-initial-mode = <2>;
			};

			ldo38_reg: LDO38 {
				regulator-name = "VDD_GRIP_1P6";
				regulator-min-microvolt = <1600000>;
				regulator-max-microvolt = <1600000>;
				regulator-ramp-delay = <12000>;
				regulator-initial-mode = <0>;
			};

			ldo39_reg: LDO39 {
				regulator-name = "vdd_ldo39";
				regulator-min-microvolt = <1000000>;
				regulator-max-microvolt = <1050000>;
			};

			ldo40_reg: LDO40 {
				regulator-name = "vdd_ldo40";
				regulator-min-microvolt = <1800000>;
				regulator-max-microvolt = <1800000>;
				regulator-ramp-delay = <12000>;
				regulator-initial-mode = <2>;
			};

			ldo41_reg: LDO41 {
				regulator-name = "vdd_ldo41";
				regulator-min-microvolt = <1800000>;
				regulator-max-microvolt = <1800000>;
			};

			ldo42_reg: LDO42 {
				regulator-name = "vdd_ldo42";
				regulator-min-microvolt = <1800000>;
				regulator-max-microvolt = <3375000>;
				regulator-always-on;
				regulator-ramp-delay = <12000>;
				regulator-initial-mode = <2>;
			};

			ldo44_reg: LDO44 {
				regulator-name = "VDDIO_1.8V_VT";
				regulator-min-microvolt = <1800000>;
				regulator-max-microvolt = <1800000>;
			};

			ldo45_reg: LDO45 {
				regulator-name = "VDDA_2.8V_WIDESUB";
				regulator-min-microvolt = <2800000>;
				regulator-max-microvolt = <2800000>;
			};
		};
	};
};

&mif_pdata {
	/* GPIOs for HW REV */
	/* XGPIO27-CP_REV0, XGPIO26-CP_REV1, XGPIO25-CP_REV2, XGPIO24-CP_REV3
	 * XGPIO13-AP_REV0, XGPIO12-AP_REV1, XGPIO11-AP_REV2, XGPIO10-AP_REV3
	 * XGPIO09-AP_REV3 */
	gpios = <&gpg1 5 0>, <&gpg1 4 0>, <&gpg1 3 0>, <&gpg1 2 0>,
		<&gpg1 1 0>;
	pinctrl-names = "default";
};

&hsi2c_11 {
	#address-cells = <1>;
	#size-cells = <0>;
	clock-frequency = <10000>;
	status = "okay";
	pinctrl-names = "default";
	pinctrl-0 = <&grip_i2c>;

	a96t3x6-i2c@20 {
		compatible = "a96t3x6";
		reg = <0x20>;
		status = "okay";
		pinctrl-names = "default";
		pinctrl-0 = <&grip_irq>;
		interrupt-parent = <&gpa3>;
		interrupts = <0 0 0>;

		a96t3x6,irq_gpio = <&gpa3 0 0>;
		a96t3x6,fw_path = "a96t365_r7.bin";
		a96t3x6,dvdd_vreg_name = "VDD_GRIP_1P6";
		a96t3x6,firmup_cmd = <0x60>;
	};
};

&hsi2c_24 { /* s2mpb03_pmic */
	#address-cells = <1>;
	#size-cells = <0>;
	status = "okay";
	s2mpb03_pmic@56 {
		compatible = "samsung,s2mpb03pmic";
		reg = <0x56>;

		s2mpb03,wakeup;

		regulators {
			_ldo1_reg: s2mpb03-ldo1 {
				regulator-name = "VDDD_1.05V_CAM";
				regulator-min-microvolt = <1050000>;
				regulator-max-microvolt = <1050000>;
			};

			_ldo2_reg: s2mpb03-ldo2 {
				regulator-name = "VDDD_1.05V_VT";
				regulator-min-microvolt = <1050000>;
				regulator-max-microvolt = <1050000>;
			};

			_ldo3_reg: s2mpb03-ldo3 {
				regulator-name = "VDDA_1.8V_CAM";
				regulator-min-microvolt = <1800000>;
				regulator-max-microvolt = <1800000>;
			};

			_ldo4_reg: s2mpb03-ldo4 {
				regulator-name = "VDDRET_1.05V_CAM";
				regulator-min-microvolt = <700000>;
				regulator-max-microvolt = <1050000>;
			};

			_ldo5_reg: s2mpb03-ldo5 {
				regulator-name = "VDDAF_2.8V_CAM";
				regulator-min-microvolt = <2800000>;
				regulator-max-microvolt = <2800000>;
			};

			_ldo6_reg: s2mpb03-ldo6 {
				regulator-name = "VDDA_2.8V_CAM";
				regulator-min-microvolt = <2800000>;
				regulator-max-microvolt = <2950000>;
			};

			_ldo7_reg: s2mpb03-ldo7 {
				regulator-name = "VDDVM_2.8V_OIS";
				regulator-min-microvolt = <2800000>;
				regulator-max-microvolt = <2800000>;
			};
		};
	};
};

&hsi2c_34 { /* s2mpb03_pmic2 */
	#address-cells = <1>;
	#size-cells = <0>;
	status = "okay";
	s2mpb03_pmic@56 {
		compatible = "samsung,s2mpb03pmic";
		reg = <0x56>;

		s2mpb03,wakeup;

		regulators {
			__ldo1_reg: s2mpb03-ldo1 {
				regulator-name = "VDDD_1.05V_SUB";
				regulator-min-microvolt = <1050000>;
				regulator-max-microvolt = <1050000>;
			};

			__ldo2_reg: s2mpb03-ldo2 {
				regulator-name = "VDDD_1.05V_WIDESUB";
				regulator-min-microvolt = <1050000>;
				regulator-max-microvolt = <1050000>;
			};

			__ldo3_reg: s2mpb03-ldo3 {
				regulator-name = "VDDIO_1.8V_SUB";
				regulator-min-microvolt = <1800000>;
				regulator-max-microvolt = <1800000>;
			};

			__ldo4_reg: s2mpb03-ldo4 {
				regulator-name = "S2MPB03_LDO4";
				regulator-min-microvolt = <1050000>;
				regulator-max-microvolt = <1050000>;
			};

			__ldo5_reg: s2mpb03-ldo5 {
				regulator-name = "VDDA_2.9V_VT";
				regulator-min-microvolt = <2900000>;
				regulator-max-microvolt = <2900000>;
			};

			__ldo6_reg: s2mpb03-ldo6 {
				regulator-name = "VDDAF_2.8V_SUB";
				regulator-min-microvolt = <2800000>;
				regulator-max-microvolt = <2800000>;
			};

			__ldo7_reg: s2mpb03-ldo7 {
				regulator-name = "VDD_2.8V_OIS";
				regulator-min-microvolt = <2800000>;
				regulator-max-microvolt = <2800000>;
			};
		};
	};
};

&hsi2c_15 {
	status = "okay";
	rtcfmradio@64 {
		compatible = "richwave,rtc6213n", "rtc6213n";
		reg = <0x64>;
		interrupts = <1 0 0>;
		interrupt-parent = <&gpa2>;
		pinctrl-names = "default";
		pinctrl-0 = <&fmradio_i2c &fmradio_int>;
		fmint-gpio = <&gpa2 1 0>;
		volume_db;
		radio_vol = <44 43 39 36 33 30 27 24 21 19 15 12 10 8 6 4>;
	};
};

&dwmmc_2 {
	#address-cells = <1>;
	#size-cells = <0>;
	status = "okay";
	num-slots = <1>;
	supports-4bit;
	supports-cmd23;
	supports-erase;
	supports-highspeed;
	sd-uhs-sdr50;
	sd-uhs-sdr104;
	card-detect-gpio;
	bypass-for-allpass;
	use-fine-tuning;
	card-init-hwacg-ctrl;
	skip-init-mmc-scan;
	qos-dvfs-level = <336000>;
	fifo-depth = <0x40>;
	desc-size = <4>;
	card-detect-delay = <200>;
	data-timeout = <200>;
	hto-timeout = <80>;
	ssc-rate = <3>;
	samsung,dw-mshc-ciu-div = <3>;
	clock-frequency = <800000000>;
	samsung,dw-mshc-sdr-timing = <3 0 2 0>;
	samsung,dw-mshc-ddr-timing = <3 0 2 1>;
	samsung,dw-mshc-sdr50-timing = <3 0 4 2>;
	samsung,dw-mshc-sdr104-timing = <3 0 3 0>;

	num-ref-clks = <9>;
	ciu_clkin = <25 50 50 25 50 100 200 50 50>;

	/* Swapping clock drive strength */
	clk-drive-number = <6>;
	pinctrl-names = "default",
		"fast-slew-rate-1x",
		"fast-slew-rate-1_5x",
		"fast-slew-rate-2x",
		"fast-slew-rate-2_5x",
		"fast-slew-rate-3x",
		"fast-slew-rate-4x";
	pinctrl-0 = <&sd2_clk &sd2_cmd &sd2_bus1 &sd2_bus4 &dwmmc2_cd_ext_irq>;
	pinctrl-1 = <&sd2_clk_fast_slew_rate_1x>;
	pinctrl-2 = <&sd2_clk_fast_slew_rate_1_5x>;
	pinctrl-3 = <&sd2_clk_fast_slew_rate_2x>;
	pinctrl-4 = <&sd2_clk_fast_slew_rate_2_5x>;
	pinctrl-5 = <&sd2_clk_fast_slew_rate_3x>;
	pinctrl-6 = <&sd2_clk_fast_slew_rate_4x>;

	card-detect = <&gpa1 5 0xf>;
	sec-sd-slot-type = <2>; /* Hybrid Tray SD slot */
	slot@0 {
		reg = <0>;
		bus-width = <4>;
		disable-wp;
	};
};

&abox_gic {
	status = "okay";
};

&abox {
	status = "okay";

	ext_bin_0: ext_bin@0 {
		status = "okay";
		samsung,name = "spkamp.bin";
		samsung,area = <1>; /* 0:SRAM, 1:DRAM, 2:VSS */
		samsung,offset = <0x502000>;
	};
	ext_bin_3: ext_bin@3 {
		status = "okay";
		samsung,name = "SoundBoosterParam.bin";
		samsung,area = <1>;
		samsung,offset = <0x4FC000>;
	};
	ext_bin_6: ext_bin@6 {
		status = "okay";
		samsung,name = "param_ti.bin";
		samsung,area = <1>;
		samsung,offset = <0x600000>;
	};
	abox_adaptation: abox_adaptation {
		compatible = "samsung,abox-adaptation";
		#sound-dai-cells = <1>;
		abox = <&abox>;
	};
};

&hsi2c_7 {
	#address-cells = <1>;
	#size-cells = <0>;
	status = "okay";
	rt5665: rt5665@1b {
		compatible = "realtek,rt5665";
		reg = <0x1b>;
		pinctrl-names = "default";
		pinctrl-0 = <&codec_i2c &codec_irq>;
		interrupt-parent = <&gpa2>;
		interrupts = <2 0 0>;
		#sound-dai-cells = <1>;
		realtek,in1-differential;
		realtek,in2-differential;
		realtek,in4-differential;
		realtek,jd-src = <1>;
		realtek,sar-hs-type = <700>;
		realtek,sar-pb-vth0 = <95>;
		realtek,sar-pb-vth1 = <139>;
		realtek,sar-pb-vth2 = <246>;
		realtek,sar-pb-vth3 = <580>;
		imp_table = <
			/*min max gain bias*/
			0x0000 0x000d 3 6 // 8 ohm
			0x000e 0x0019 1 6 // 16 ohm
			0x001a 0x0035 0 6 // 32 ohm
			0x0036 0x0067 0 6 // 64 ohm
			0x0068 0xffff 0 6 // > 100 ohm
		>;

		realtek,offset-comp = <0x0078 0x0090 0x00b0 0x00c0
					0x00f0 0x0110 0x0130 0x0180
					0x01e0 0x0200 0x02a0 0x0300
					0x03a0 0x0400 0x0500 0x0600>;
		realtek,offset-comp-r = <0x001a 0x001f 0x0020 0x002a
					0x0030 0x0040 0x0050 0x0060
					0x006f 0x007f 0x00a0 0x00b0
					0x00cf 0x0100 0x0120 0x0160>;
		realtek,regulator_1v8 = <&ldo33_reg>;
		realtek,regulator_3v3 = <&ldo36_reg>;

		realtek,rek-first-playback;
	};
};

&hsi2c_18 {
	#address-cells = <1>;
	#size-cells = <0>;
	status = "okay";
	clock-frequency = <400000>;
	tas2562: tas2562@4c {
		#sound-dai-cells = <1>;
		compatible = "ti,tas2562";
		reg = <0x4c>;
		pinctrl-names = "default";
		pinctrl-0 = <&amp_i2c &amp_en &amp_int>;
		ti,left-channel = <0x4c>;
		ti,channels = <1>;
		ti,reset-gpio = <&gpa2 7 0>;
		ti,irq-gpio = <&gpm2 0 0>;
		ti,port_id = <0x1000>;
		ti,re_min = <2621440>;
		ti,re_max = <5242880>;
		ti,f0_min = <419430400>;
		ti,f0_max = <629145600>;
		ti,q_min = <524288>;
		ti,q_max = <1572864>;
		status = "ok";
	};
};

&pcie_0 {
    pinctrl-names = "default","idle";
    pinctrl-0 = <&pcie0_clkreq &pcie0_perst &pcie_wake &cfg_wlanen &wlan_host_wake>;
    pinctrl-1 = <&pcie0_perst &pcie_wake &cfg_wlanen &wlan_host_wake>;
    status = "okay";
    use-sysmmu = "true";
    use-cache-coherency = "true";
    use-msi = "false";
    ep-device-type = <EP_BCM_WIFI>;
};
